VERSION ""

NS_ :

BS_:

BU_:

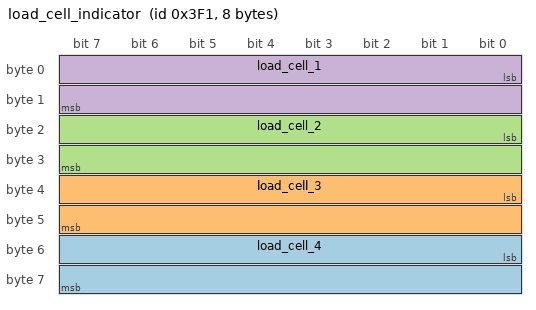
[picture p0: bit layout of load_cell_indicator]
BO_ 1009 load_cell_indicator: 8 Vector__XXX
 SG_ load_cell_4 : 48|16@1+ (1,0) [0|65535] "" Vector__XXX
 SG_ load_cell_3 : 32|16@1+ (1,0) [0|65535] "" Vector__XXX
 SG_ load_cell_2 : 16|16@1+ (1,0) [0|65535] "" Vector__XXX
 SG_ load_cell_1 : 0|16@1+ (1,0) [0|65535] "" Vector__XXX
